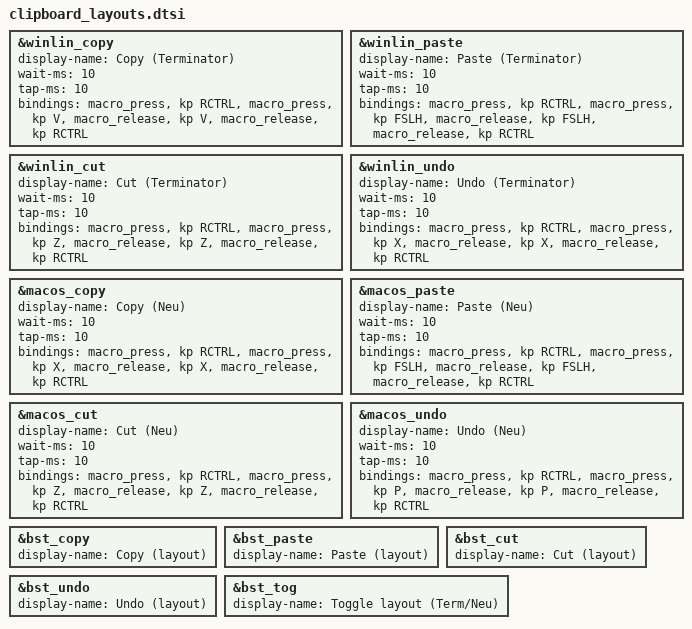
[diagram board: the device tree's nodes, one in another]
/*
 * Layout-aware clipboard/edit keys for two custom Windows keyboard layouts.
 *
 * The board ships these as "OS-dependent" (Windows/Linux vs macOS) bistable
 * behaviors, but in practice both slots use the same modifier and only the
 * physical key positions differ -- because they target two different keyboard
 * *layouts* used on different physical keyboards, not two operating systems.
 * `bst_tog` (ZBS_TOG) flips between them.
 *
 * Modifier: RIGHT Ctrl (RC). The Neu layout remaps LEFT Ctrl, so LC(...) does
 * not produce a clean Ctrl chord there; Right Ctrl is untouched in both layouts.
 *
 *   slot 0  (label winlin_*) -> "Terminator" layout (kbdterm)
 *   slot 1  (label macos_*)  -> "Neu" layout (kbdneu)
 *
 * These layouts remap the letters, so plain Ctrl+C/V/X/Z (which ZMK sends from
 * the physical QWERTY positions) miss the C/V/X/Z virtual keys. We instead press
 * the physical key that produces the target character under each layout. The
 * mapping is read off each layout's `scancode_to_vk` table, then the PC Set-1
 * scancode is translated back to its US-QWERTY physical key (= the ZMK keycode):
 *
 *   Terminator (slot 0):  C@0x2F->V   V@0x35->/   X@0x2C->Z   Z@0x2D->X
 *   Neu        (slot 1):  C@0x2D->X   V@0x35->/   X@0x2C->Z   Z@0x19->P
 *
 * Undo/cut/copy/paste use an explicit press/release macro (key up BEFORE Ctrl
 * up). A plain `&kp RC(...)` was releasing RCtrl while the letter was still
 * down; AHK then saw a bare Z (Neu) and typed it.
 *
 * We amend the macro nodes declared in the board's behaviors_macros.dtsi (which
 * the bst_copy/paste/cut/undo behaviors dispatch to) and relabel their
 * display-names from "OS" wording to the actual layout names.
 */

/* --- slot 0: Terminator layout (Right Ctrl modifier) --- */
&winlin_copy {
	display-name = "Copy (Terminator)";
	wait-ms = <10>;
	tap-ms = <10>;
	bindings
		= <&macro_press &kp RCTRL>
		, <&macro_press &kp V>
		, <&macro_release &kp V>
		, <&macro_release &kp RCTRL>;
};

&winlin_paste {
	display-name = "Paste (Terminator)";
	wait-ms = <10>;
	tap-ms = <10>;
	bindings
		= <&macro_press &kp RCTRL>
		, <&macro_press &kp FSLH>
		, <&macro_release &kp FSLH>
		, <&macro_release &kp RCTRL>;
};

&winlin_cut {
	display-name = "Cut (Terminator)";
	wait-ms = <10>;
	tap-ms = <10>;
	bindings
		= <&macro_press &kp RCTRL>
		, <&macro_press &kp Z>
		, <&macro_release &kp Z>
		, <&macro_release &kp RCTRL>;
};

&winlin_undo {
	display-name = "Undo (Terminator)";
	wait-ms = <10>;
	tap-ms = <10>;
	bindings
		= <&macro_press &kp RCTRL>
		, <&macro_press &kp X>
		, <&macro_release &kp X>
		, <&macro_release &kp RCTRL>;
};

/* --- slot 1: Neu layout (Right Ctrl modifier) --- */
&macos_copy {
	display-name = "Copy (Neu)";
	wait-ms = <10>;
	tap-ms = <10>;
	bindings
		= <&macro_press &kp RCTRL>
		, <&macro_press &kp X>
		, <&macro_release &kp X>
		, <&macro_release &kp RCTRL>;
};

&macos_paste {
	display-name = "Paste (Neu)";
	wait-ms = <10>;
	tap-ms = <10>;
	bindings
		= <&macro_press &kp RCTRL>
		, <&macro_press &kp FSLH>
		, <&macro_release &kp FSLH>
		, <&macro_release &kp RCTRL>;
};

&macos_cut {
	display-name = "Cut (Neu)";
	wait-ms = <10>;
	tap-ms = <10>;
	bindings
		= <&macro_press &kp RCTRL>
		, <&macro_press &kp Z>
		, <&macro_release &kp Z>
		, <&macro_release &kp RCTRL>;
};

&macos_undo {
	display-name = "Undo (Neu)";
	wait-ms = <10>;
	tap-ms = <10>;
	bindings
		= <&macro_press &kp RCTRL>
		, <&macro_press &kp P>
		, <&macro_release &kp P>
		, <&macro_release &kp RCTRL>;
};

/* --- selector display-names: it's a layout switch, not an OS switch --- */
&bst_copy  { display-name = "Copy (layout)"; };
&bst_paste { display-name = "Paste (layout)"; };
&bst_cut   { display-name = "Cut (layout)"; };
&bst_undo  { display-name = "Undo (layout)"; };
&bst_tog   { display-name = "Toggle layout (Term/Neu)"; };
